# TC37XPD register map
Vendor: Infineon; Series: ATVMC; File version: 100
CPU: other r0p0, little endian, MPU, FPU, vendor SysTick, 4 interrupt priority bits
Registers are 32-bit, read-write, reset 0x0 unless marked. A register's access mark holds for its fields unless they carry their own. Offsets are from the block's base; [hi:lo] are bit positions; {n}, {i} and the like mark numbered series.

## ERAY0 (part 2 of 3) — ERAY
Base 0xF001C000
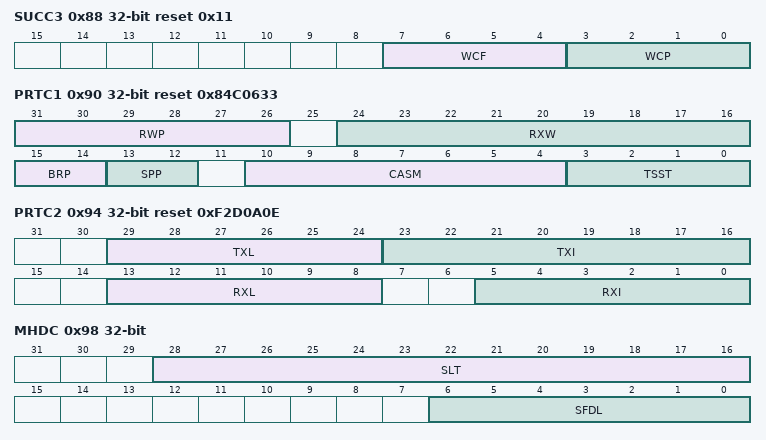
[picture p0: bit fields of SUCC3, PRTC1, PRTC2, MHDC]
0x88 SUCC3 reset 0x11 — SUC Configuration Register 3 resetvalue={Application Reset:0x11}
  [7:4] WCF — Maximum Without Clock Correction Fatal gMaxWithoutClockCorrecti on Fatal WCF. Defines the number of consecutive even odd cycle pairs with missing clock correction terms that will cause a transition from 8220 NORMAL ACTIVE 8221 or 8220 NORMAL PASSIVE 8221 to 8220 HALT 8221 state. Must be identical in all nodes of a cluster. Valid values are 1 to 15 1 H to F H cycle pairs.
  [3:0] WCP — Maximum Without Clock Correction Passive gMaxWithoutClockCorrectionPassive WCP. Defines the number of consecutive even odd cycle pairs with missing clock correction terms that will cause a transition from 8220 NORMAL ACTIVE 8221 to 8220 NORMAL PASSIVE 8221 state. Must be identical in all nodes of a cluster. Valid values are 1 to 15 1 H to F H cycle pairs.
0x8C NEMC — NEM Configuration Register resetvalue={Application Reset:0x0}
  [3:0] NML — Network Management Vector Length gNetworkManagementVectorLength NML. These bits configure the length of the NM Vector. The configured length must be identical in all nodes of a cluster. Valid values are 0 to 12 0 H to C H bytes.
0x90 PRTC1 reset 0x84C0633 — PRT Configuration Register 1 resetvalue={Application Reset:0x084C0633}
  [31:26] RWP — Repetitions of Tx Wakeup Pattern pWakeupPattern RWP. Configures the number of repetitions sequences of the Tx wakeup symbol. Valid values are 2 to 63 2 H to 3F H .
  [24:16] RXW — Wakeup Symbol Receive Window Length gdWakeupSymbolRxWindow RXW. Configures the number of Bit Times used by the node to test the duration of the received wakeup pattern. Must be identical in all nodes of a cluster. Valid values are 76 to 301 4C H to 12D H Bit Times.
  [15:14] BRP — Baud Rate Prescaler gdSampleClockPeriod pSamplePerMicrotick BRP. The baud rate prescaler configures the baud rate on the FlexRay 8482 bus. The baud rates listed below are valid with a sample clock f SCLK 80 160 MHz. One bit time always consists of 8 samples independent of the configured baud rate.
  [13:12] SPP — Strobe Point Position SPP. Defines the sample count value for strobing. The strobed bit value is set to the voted value when the sample count is incremented to the value configured by SPP. The current revision 2.1 of the FlexRay 8482 protocol requires that SPP 00 B . The alternate strobe point positions could be used to compensate for asymmetries in the physical layer.
  [10:4] CASM — Collision Avoidance Symbol Maximum gdCASRxLowMax CASM. Configures the upper limit of the acceptance window for a collision avoidance symbol CAS . Valid values are 67 to 99 43 H to 63 H . Most significant bit of CASM is hard wired to 1 and can not be modified.
  [3:0] TSST — Transmission Start Sequence Transmitter gdTSSTransmitter TSST. Configures the duration of the Transmission Start Sequence TSS in terms of Bit Times 1 bit time 160 4 160 Microticks 160 100ns at 10Mbps . Must be identical in all nodes of a cluster. Valid values are 3 to 15 3 H to F H Bit Times.
0x94 PRTC2 reset 0xF2D0A0E — PRT Configuration Register 2 resetvalue={Application Reset:0x0F2D0A0E}
  [29:24] TXL — Wakeup Symbol Transmit Low gdWakeupSymbolTxLow TXL. Configures the number of Bit Times used by the node to transmit the low phase of the wakeup symbol. Must be identical in all nodes of a cluster. Valid values are 15 to 60 F H to 3C H Bit Times.
  [23:16] TXI — Wakeup Symbol Transmit Idle gdWakeupSymbolTxIdle TXI. Configures the number of Bit Times used by the node to transmit the idle phase of the wakeup symbol. Must be identical in all nodes of a cluster. Valid values are 45 to 180 2D H to B4 H Bit Times.
  [13:8] RXL — Wakeup Symbol Receive Low gdWakeupSymbolRxLow RXL. Configures the number of Bit Times used by the node to test the duration of the low phase of the received wakeup symbol. Must be identical in all nodes of a cluster. Valid values are 10 to 55 A H to 37 H Bit Times.
  [5:0] RXI — Wakeup Symbol Receive Idle gdWakeupSymbolRxIdle RXI. Configures the number of Bit Times used by the node to test the duration of the idle phase of the received wakeup symbol. Must be identical in all nodes of a cluster. Valid values are 14 to 59 E H to 3B H Bit Times.
0x98 MHDC — MHD Configuration Register resetvalue={Application Reset:0x0}
  [28:16] SLT — Start of Latest Transmit pLatestTx SLT. Configures the maximum minislot value allowed before inhibiting Frame transmission in the dynamic segment of the cycle. There is no transmission dynamic segment if SLT is reset to zero. Valid values are 0 to 7981 0 to 1F2D H minislots.
  [6:0] SFDL — Static Frame Data Length gPayloadLengthStatic SFDL. Configures the cluster wide payload length for all Frames sent in the static segment in double byte. The payload length must be identical in all nodes of a cluster. Valid values are 0 to 127 0 to 7F H .
0xA0 GTUC01 reset 0x280 — GTU Configuration Register 1 resetvalue={Application Reset:0x280}
  [19:0] UT — Microtick per Cycle pMicroPerCycle UT. Configures the duration of the communication cycle in Microticks. Valid values are 640 to 640000 280 H to 9C400 H Microticks.
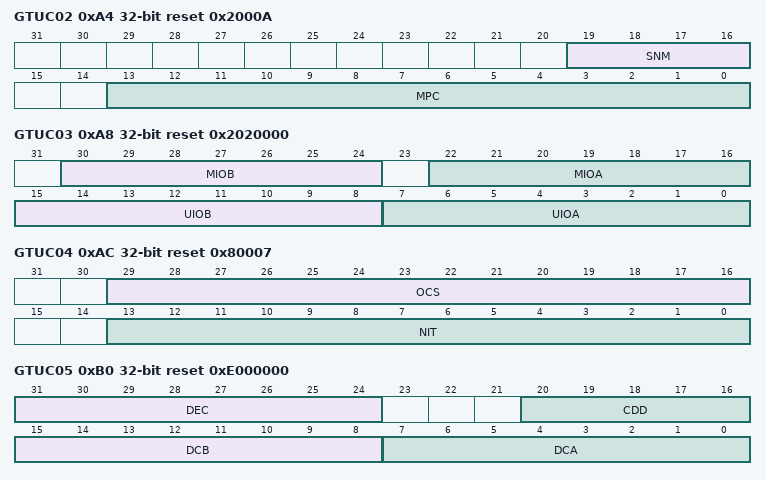
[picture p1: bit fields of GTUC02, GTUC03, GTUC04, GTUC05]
0xA4 GTUC02 reset 0x2000A — GTU Configuration Register 2 resetvalue={Application Reset:0x2000A}
  [19:16] SNM — Sync Node Max gSyncNodeMax SNM. Maximum number of Frames within a cluster with SYNC Frame indicator bit SYN set to 1. Must be identical in all nodes of a cluster. Valid values are 2 to 15 2 H to F H .
  [13:0] MPC — Macrotick Per Cycle gMacroPerCycle MPC. Configures the duration of one communication cycle in Macroticks. The cycle length must be identical in all nodes of a cluster. Valid values are 10 to 16000 A H to 3E80 H Macroticks.
0xA8 GTUC03 reset 0x2020000 — GTU Configuration Register 3 resetvalue={Application Reset:0x2020000}
  [30:24] MIOB — Macrotick Initial Offset Channel B gMacroInitialOffset B MIOB. Configures the number of Macroticks between the static slot boundary and the subsequent Macrotick boundary of the secondary time reference point based on the nominal Macrotick duration. Must be identical in all nodes of a cluster. Valid values are 2 to 72 2 H to 48 H Macroticks.
  [22:16] MIOA — Macrotick Initial Offset Channel A gMacroInitialOffset A MIOA. Configures the number of Macroticks between the static slot boundary and the subsequent Macrotick boundary of the secondary time reference point based on the nominal Macrotick duration. Must be identical in all nodes of a cluster. Valid values are 2 to 72 2 H to 48 H Macroticks.
  [15:8] UIOB — Microtick Initial Offset Channel B pMicroInitialOffset B UIOB. Configures the number of Microticks between the actual time reference point on channel B and the subsequent Macrotick boundary of the secondary time reference point. The parameter depends on pDelayCompensation B and therefore has to be set for each channel independently. Valid values are 0 to 240 0 H to F0 H Microticks.
  [7:0] UIOA — Microtick Initial Offset Channel A pMicroInitialOffset A UIOA. Configures the number of Microticks between the actual time reference point on channel A and the subsequent Macrotick boundary of the secondary time reference point. The parameter depends on pDelayCompensation A and therefore has to be set for each channel independently. Valid values are 0 to 240 0 H to F0 H Microticks.
0xAC GTUC04 reset 0x80007 — GTU Configuration Register 4 resetvalue={Application Reset:0x080007}
  [29:16] OCS — Offset Correction Start gOffsetCorrectionStart 1 OCS. Determines the start of the offset correction within the network idle time NIT phase calculated from start of cycle. Must be identical in all nodes of a cluster. For cluster consisting of E Ray implementations only it is sufficient to program OCS NIT 1. Valid values are 8 to 15998 8 H to 3E7E H Macroticks.
  [13:0] NIT — Network Idle Time Start gMacroPerCycle gdNIT 1 NIT. Configures the starting point of the Network Idle Time NIT at the end of the communication cycle expressed in terms of Macroticks from the beginning of the cycle. The start of network idle time NIT is recognized if Macrotick gMacroPerCycle gdNIT 1 and the increment pulse of Macrotick is set. Must be identical in all nodes of a cluster. Valid values are 7 to 15997 7 H to 3E7D H Macroticks.
0xB0 GTUC05 reset 0xE000000 — GTU Configuration Register 5 resetvalue={Application Reset:0x0E000000}
  [31:24] DEC — Decoding Correction pDecodingCorrection DEC. Configures the decoding correction value used to determine the primary time reference point. Valid values are 14 to 143 E H to 8F H Microticks.
  [20:16] CDD — Cluster Drift Damping pClusterDriftDamping CDD. Configures the cluster drift damping value used in clock synchronization to minimize accumulation of rounding errors. Valid values are 0 to 20 0 H to 14 H Microticks.
  [15:8] DCB — Delay Compensation Channel B pDelayCompensation B DCB. Used to compensate for reception delays on channel B. This covers assumed propagation delay up to cPropagationDelayMax for Microticks in the range of 0.0125 to 0.05 160 181 s. In practice the minimum of the propagation delays of all sync nodes should be applied. Valid values are 0 to 200 0 H to C8 H Microticks.
  [7:0] DCA — Delay Compensation Channel A pDelayCompensation A DCA. Used to compensate for reception delays on channel A. This covers assumed propagation delay up to cPropagationDelayMax for Microticks in the range of 0.0125 160 181 s to 0.05 160 181 s. In practice the minimum of the propagation delays of all sync nodes should be applied. Valid values are 0 to 200 0 H to C8 H Microticks.
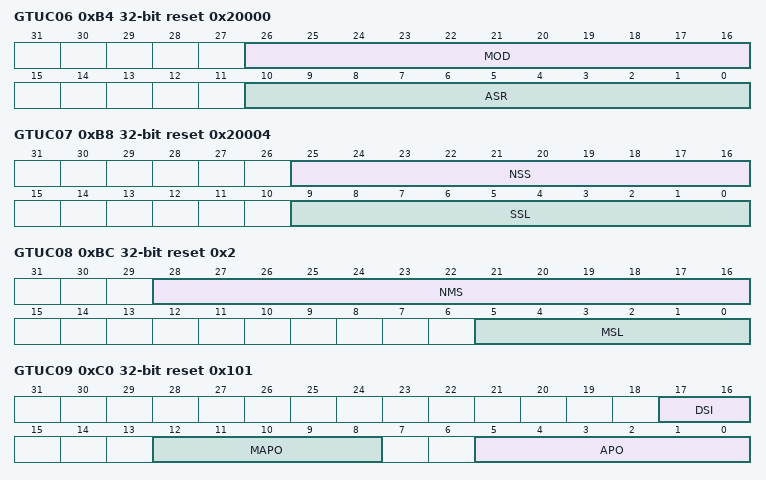
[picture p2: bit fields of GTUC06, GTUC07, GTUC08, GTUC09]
0xB4 GTUC06 reset 0x20000 — GTU Configuration Register 6 resetvalue={Application Reset:0x20000}
  [26:16] MOD — Maximum Oscillator Drift pdMaxDrift 1 MOD. Maximum drift offset between two nodes that operate with unsynchronized clocks over one communication cycle in Microticks. Valid values are 2 to 1923 2 H to 783 H Microticks.
  [10:0] ASR — Accepted Startup Range pdAcceptedStartupRange ASR. Number of Microticks constituting the expanded range of measured deviation for startup Frames during integration. Valid values are 0 to 1875 0 H to 753 H Microticks.
0xB8 GTUC07 reset 0x20004 — GTU Configuration Register 7 resetvalue={Application Reset:0x20004}
  [25:16] NSS — Number of Static Slots gNumberOfStaticSlots NSS. Configures the number of static slots in a cycle. At least 2 coldstart nodes must be configured to startup a FlexRay 8482 network. The number of static slots must be identical in all nodes of a cluster. Valid values are 2 to 1023 2 H to 3FF H .
  [9:0] SSL — Static Slot Length gdStaticSlot SSL. Configures the duration of a static slot in Macroticks. The static slot length must be identical in all nodes of a cluster. Valid values are 4 to 659 4 H to 293 H Macroticks.
0xBC GTUC08 reset 0x2 — GTU Configuration Register 8 resetvalue={Application Reset:0x2}
  [28:16] NMS — Number of Minislots gNumberOfMinislots NMS. Configures the number of minislots within the dynamic segment of a cycle. The number of minislots must be identical in all nodes of a cluster. Valid values are 0 to 7986 0 H to 1F32 H .
  [5:0] MSL — Minislot Length gdMinislot MSL. Configures the duration of a minislot in Macroticks. The minislot length must be identical in all nodes of a cluster. Valid values are 2 to 63 2 H to 3F H Macroticks.
0xC0 GTUC09 reset 0x101 — GTU Configuration Register 9 resetvalue={Application Reset:0x101}
  [17:16] DSI — Dynamic Slot Idle Phase gdDynamicSlotIdlePhase DSI. The duration of the dynamic slot idle phase has to be greater or equal than the idle detection time. Must be identical in all nodes of a cluster. Valid values are 0 to 2 Minislot.
  [12:8] MAPO — Minislot Action Point Offset gd Minislot Action Point Offset MAPO. Configures the action point offset in Macroticks within the minislots of the dynamic segment. Must be identical in all nodes of a cluster. Valid values are 1 to 31 1 H to 1F H Macroticks.
  [5:0] APO — Action Point Offset gdActionPointOffset APO. Configures the action point offset in Macroticks within static slots and symbol window. Must be identical in all nodes of a cluster. Valid values are 1 to 63 1 H to 3F H Macroticks.
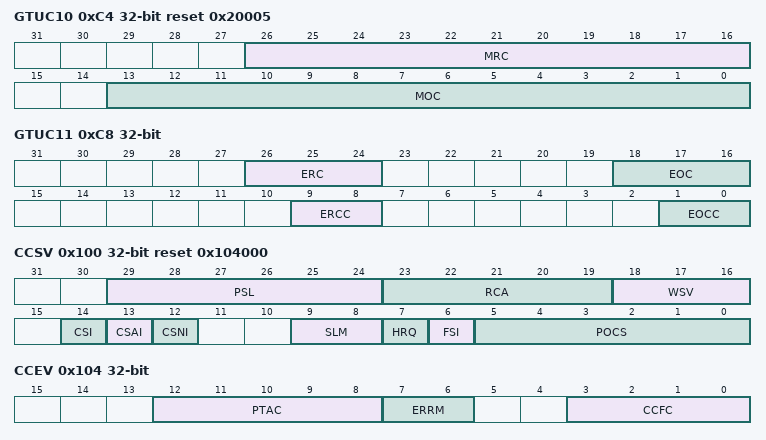
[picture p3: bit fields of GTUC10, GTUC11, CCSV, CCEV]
0xC4 GTUC10 reset 0x20005 — GTU Configuration Register 10 resetvalue={Application Reset:0x20005}
  [26:16] MRC — Maximum Rate Correction pRateCorrectionOut MRC. Holds the maximum permitted rate correction value to be applied by the internal clock synchronization algorithm. The communication controller checks only the internal rate correction value against the maximum rate correction value absolute value . Valid values are 2 to 1923 2 H to 783 H Microticks.
  [13:0] MOC — Maximum Offset Correction pOffsetCorrectionOut MOC. Holds the maximum permitted offset correction value to be applied by the internal clock synchronization algorithm absolute value . The Communication Controller checks only the internal offset correction value against the maximum offset correction value. Valid values are 5 to 15266 5 H to 3BA2 H Microticks.
0xC8 GTUC11 — GTU Configuration Register 11 resetvalue={Application Reset:0x0}
  [26:24] ERC — External Rate Correction pExternRateCorrection ERC. Holds the external rate correction value in Microticks to be applied by the internal clock synchronization algorithm. The value is subtracted added from to the calculated rate correction value. The value is applied during network idle time NIT . Can be modified in 8220 DEFAULT CONFIG 8221 or 8220 CONFIG 8221 state only. Valid values are 0 to 7 Microticks.
  [18:16] EOC — External Offset Correction pExternOffsetCorrection EOC. Holds the external clock offset correction value in Microticks to be applied by the internal synchronization algorithm. The value is subtracted added from to the calculated offset correction value. The value is applied during network idle time NIT . May be modified in 8220 DEFAULT CONFIG 8221 or 8220 CONFIG 8221 state only. Valid values are 0 to 7 Microticks.
  [9:8] ERCC — External Rate Correction Control pExternRateControl ERCC. By writing to ERCC the external rate correction is enabled as specified below. Should be modified only outside network idle time NIT .
  [1:0] EOCC — External Offset Correction Control pExternOffsetControl EOCC. By writing to EOCC the external offset correction is enabled as specified below. Should be modified only outside network idle time NIT .
0x100 CCSV ro reset 0x104000 — Communication Controller Status Vector resetvalue={Application Reset:0x104000}
  [29:24] PSL — POC Status Log PSL. Status of CCSV.POCS immediately before entering 8220 HALT 8221 state. Set when entering 8220 HALT 8221 state. Set to 8220 HALT 8221 when FREEZE command is applied during 8220 HALT 8221 state. Reset to 000000 B when leaving 8220 HALT 8221 state.
  [23:19] RCA — Remaining Coldstart Attempts vRemainingColdstartAttempts RCA. Indicates the number of remaining coldstart attempts. The RUN command resets this counter to the maximum number of coldstart attempts as configured by SUCC1.CSA.
  [18:16] WSV — Wakeup Status vPOC WakeupStatus WSV. Indicates the status of the current wakeup attempt. Reset by CHI command 8220 RESET STATUS INDICATORS 8221 or by transition from 8220 HALT 8221 to 8220 DEFAULT CONFIG 8221 state.
  [14] CSI — Cold Start Inhibit vColdStartInhibit CSI. Indicates that the node is disabled from cold starting. The flag is set whenever the POC enters 8220 READY 8221 state due to CHI command 8220 READY 8221 . The flag has to be reset under control of the Host by CHI command 8220 ALLOW COLDSTART 8221 SUCC1.CMD 160 160 1001 B .
  [13] CSAI — Coldstart Abort Indicator CSAI. Coldstart aborted. Reset by CHI command 8220 RESET STATUS INDICATORS 8221 or by transition from 8220 HALT 8221 to 8220 DEFAULT CONFIG 8221 state or from 8220 READY 8221 to 8220 STARTUP 8221 state.
  [12] CSNI — Coldstart Noise Indicator vPOC ColdstartNoise CSNI. Indicates that the cold start procedure occurred under noisy conditions. Reset by CHI command 8220 RESET STATUS INDICATORS 8221 or by transition from 8220 HALT 8221 to 8220 DEFAULT CONFIG 8221 state or from 8220 READY 8221 to 8220 STARTUP 8221 state.
  [9:8] SLM — Slot Mode vPOC SlotMode SLM. Indicates the actual slot mode of the POC in states READY WAKEUP STARTUP NORMAL ACTIVE and NORMAL PASSIVE. Default is 8220 SINGLE 8221 . Changes to 8220 ALL 8221 depending on configuration bit SUCC1.TSM. In 8220 NORMAL ACTIVE 8221 or 8220 NORMAL PASSIVE 8221 state the CHI command 8220 ALL SLOTS 8221 will change the slot mode from 8220 SINGLE 8221 over 8220 ALL PENDING 8221 to 8220 ALL 8221 . Set to SINGLE in all other states.
  [7] HRQ — Halt Request vPOC CHIHaltRequest HRQ. Indicates that a request from the Host has been received to halt the POC at the end of the communication cycle. Reset by transition from 8220 HALT 8221 to 8220 DEFAULT CONFIG 8221 state or when entering 8220 READY 8221 state.
  [6] FSI — Freeze Status Indicator vPOC Freeze FSI. Indicates that the POC has entered the 8220 HALT 8221 state due to CHI command 8220 FREEZE 8221 or due to an error condition requiring an immediate POC halt. Reset by transition from 8220 HALT 8221 to 8220 DEFAULT CONFIG 8221 state.
  [5:0] POCS — Protocol Operation Control Status POCS. 00 H ... 05 H 0F H Indicates the actual state of operation of the Communication Controller Protocol Operation Control 06 H 160 8230 160 14 H are reserved. 10 H ... 13 H Indicates the actual state of operation of the POC in the wakeup path 14 H 160 8230 160 1F H are reserved. 20 H ... 2B H Indicates the actual state of operation of the POC in the startup path 2C H 160 8230 160 3F H are reserved.
0x104 CCEV ro — Communication Controller Error Vector resetvalue={Application Reset:0x0}
  [12:8] PTAC — Passive to Active Count vAllowPassiveToActive PTAC. Indicates the number of consecutive even odd cycle pairs that have passed with valid rate and offset correction terms while the node is waiting to transit from NORMAL PASSIVE state to NORMAL ACTIVE state. The transition takes place when PTAC equals SUCC1.PTA 1.
  [7:6] ERRM — Error Mode vPOC ErrorMode ERRM. Indicates the actual error mode of the POC.
  [3:0] CCFC — Clock Correction Failed Counter vClockCorrectionFailed CCFC. The Clock Correction Failed Counter is incremented by one at the end of any odd communication cycle where either the missing offset correction error or missing rate correction error are active. The Clock Correction Failed Counter is reset to 0 at the end of an odd communication cycle if neither the offset correction failed nor the rate correction failed errors are active. The Clock Correction Failed Counter stops at 15.
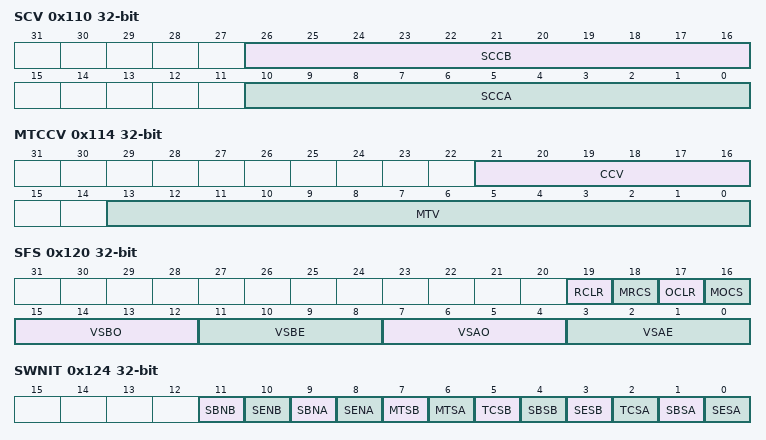
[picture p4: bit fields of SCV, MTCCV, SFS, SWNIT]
0x110 SCV ro — Slot Counter Value resetvalue={Application Reset:0x0}
  [26:16] SCCB — Slot Counter Channel B vSlotCounter B SCCB. Current slot counter value on channel B. The value is incremented by the Communication Controller and reset at the start of a communication cycle. Valid values are 0 to 2047 0 H to 7FF H .
  [10:0] SCCA — Slot Counter Channel A vSlotCounter A SCCA. Current slot counter value on channel A. The value is incremented by the Communication Controller and reset at the start of a communication cycle. Valid values are 0 to 2047 0 H to 7FF H .
0x114 MTCCV ro — Macrotick and Cycle Counter Value resetvalue={Application Reset:0x0}
  [21:16] CCV — Cycle Counter Value vCycleCounter CCV. Current cycle counter value. The value is incremented by the Communication Controller at the start of a communication cycle. Valid values are 0 to 63 0 H to 3F H .
  [13:0] MTV — Macrotick Value vMacrotick MTV. Current Macrotick value. The value is incremented by the Communication Controller and reset at the start of a communication cycle. Valid values are 0 to 16000 0 H to 3E80 H .
0x118 RCV ro — Rate Correction Value resetvalue={Application Reset:0x0}
  [11:0] RCV — Rate Correction Value vRateCorrection RCV. Rate correction value two s complement . Calculated internal rate correction value before limitation. If the RCV value exceeds the limits defined by GTUC10.MRC flag SFS.RCLR is set to 1.
0x11C OCV ro — Offset Correction Value resetvalue={Application Reset:0x0}
  [18:0] OCV — Offset Correction Value vOffsetCorrection OCV. Offset correction value two s complement . Calculated internal offset correction value before limitation. If the OCV value exceeds the limits defined by GTUC10.MOC flag SFS.OCLR is set to 1.
0x120 SFS ro — SYNC Frame Status resetvalue={Application Reset:0x0}
  [19] RCLR — Rate Correction Limit Reached RCLR. The Rate Correction Limit Reached flag signals to the Host that the rate correction value has exceeded its limit.as defined by GTUC10.MRC. The flag is updated by the Communication Controller at start of offset correction phase.
  [18] MRCS — Missing Rate Correction Signal MRCS. The Missing Rate Correction Flag signals to the Host that no rate correction calculation can be performed because no pairs of even odd SYNC Frames were received. The flag is updated by the Communication Controller at start of offset correction phase.
  [17] OCLR — Offset Correction Limit Reached OCLR. The Offset Correction Limit Reached flag signals to the Host that the offset correction value has exceeded its limit as defined by GTUC10.MOC. The flag is updated by the Communication Controller at start of offset correction phase.
  [16] MOCS — Missing Offset Correction Signal MOCS. The Missing Offset Correction flag signals to the Host that no offset correction calculation can be performed because no SYNC Frames were received. The flag is updated by the Communication Controller at start of offset correction phase.
  [15:12] VSBO — Valid SYNC Frames Channel B odd communication cycle VSBO. Holds the number of valid SYNC Frames received on channel B in the odd communication cycle. If transmission of SYNC Frames is enabled by SUCC1.TXSY the value is incremented by one. The value is updated during the network idle time NIT of each odd communication cycle. This bit field is only valid if the channel B is assigned to the Communication Controller by SUCC1.CCHB.
  [11:8] VSBE — Valid SYNC Frames Channel B even communication cycle VSBE. Holds the number of valid SYNC Frames received on channel B in the even communication cycle. If transmission of SYNC Frames is enabled by SUCC1.TXSY the value is incremented by one. The value is updated during the network idle time NIT of each even communication cycle. This bit field is only valid if the channel B is assigned to the Communication Controller by SUCC1.CCHB.
  [7:4] VSAO — Valid SYNC Frames Channel A odd communication cycle VSAO. Holds the number of valid SYNC Frames received on channel A in the odd communication cycle. If transmission of SYNC Frames is enabled by SUCC1.TXSY the value is incremented by one. The value is updated during the network idle time NIT of each odd communication cycle. This bit field is only valid if the channel A is assigned to the Communication Controller by SUCC1.CCHA.
  [3:0] VSAE — Valid SYNC Frames Channel A even communication cycle VSAE. Holds the number of valid SYNC Frames received on channel A in the even communication cycle. If transmission of SYNC Frames is enabled by SUCC1.TXSY the value is incremented by one. The value is updated during the network idle time NIT of each even communication cycle. This bit field is only valid if the channel A is assigned to the Communication Controller by SUCC1.CCHA.
0x124 SWNIT ro — Symbol Window and Network Idle Time Status resetvalue={Application Reset:0x0}
  [11] SBNB — Slot Boundary Violation during network idle time NIT Channel B vSS BViolationB SBNB. Updated by the Communication Controller channel B at the end of the NIT.
  [10] SENB — Syntax Error during network idle time NIT Channel B vSS SyntaxErrorB SENB. Updated by the Communication Controller channel B at the end of the NIT.
  [9] SBNA — Slot Boundary Violation during network idle time NIT Channel A vSS BViolationA SBNA. Updated by the Communication Controller channel A at the end of the NIT.
  [8] SENA — Syntax Error during network idle time NIT Channel A vSS SyntaxErrorA SENA. Updated by the Communication Controller channel A at the end of the NIT.
  [7] MTSB — MTS Received on Channel B vSS ValidMTSB MTSB. Media Access Test symbol received on channel B during the proceeding symbol window. Updated by the Communication Controller for each channel at the end of the symbol window. When this bit is set to 1 also interrupt flag SIR.MTSB is set to 1.
  [6] MTSA — MTS Received on Channel A vSS ValidMTSA MTSA. Media Access Test symbol received on channel A during the proceeding symbol window. Updated by the Communication Controller for each channel at the end of the symbol window. When this bit is set to 1 also interrupt flag SIR.MTSA is set to 1.
  [5] TCSB — Transmission Conflict in Symbol Window Channel B vSS TxConflictB TCSB
  [4] SBSB — Slot Boundary Violation in Symbol Window Channel B vSS BViolationB SBSB
  [3] SESB — Syntax Error in Symbol Window Channel B vSS SyntaxErrorB SESB
  [2] TCSA — Transmission Conflict in Symbol Window Channel A vSS TxConflictA TCSA
  [1] SBSA — Slot Boundary Violation in Symbol Window Channel A vSS BViolationA SBSA
  [0] SESA — Syntax Error in Symbol Window Channel A vSS SyntaxErrorA SESA
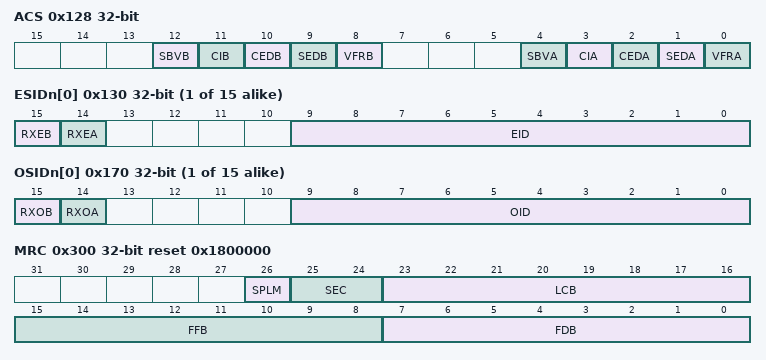
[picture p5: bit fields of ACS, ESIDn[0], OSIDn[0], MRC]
0x128 ACS — Aggregated Channel Status resetvalue={Application Reset:0x0}
  [12] SBVB — Slot Boundary Violation on Channel B vSS BViolationB SBVB. One or more slot boundary violations were observed on channel B at any time during the observation period static or dynamic slots symbol window and network idle time NIT .
  [11] CIB — Communication Indicator Channel B CIB. One or more valid Frames were received on channel B in slots that also contained any additional communication during the observation period i.e. one or more slots received a valid Frame AND had any combination of either syntax error OR content error OR slot boundary violation.
  [10] CEDB — Content Error Detected on Channel B vSS ContentErrorB CEDB. One or more Frames with a content error were received on channel B in any static or dynamic slot during the observation period.
  [9] SEDB — Syntax Error Detected on Channel B vSS SyntaxErrorB SEDB. One or more syntax errors in static or dynamic slots symbol window and network idle time NIT were observed on channel B.
  [8] VFRB — Valid Frame Received on Channel B vSS ValidFrameB VFRB. One or more valid Frames were received on channel B in any static or dynamic slot during the observation period.
  [4] SBVA — Slot Boundary Violation on Channel A vSS BViolationA SBVA. One or more slot boundary violations were observed on channel A at any time during the observation period static or dynamic slots symbol window and network idle time NIT .
  [3] CIA — Communication Indicator Channel A CIA. One or more valid Frames were received on channel A in slots that also contained any additional communication during the observation period i.e. one or more slots received a valid Frame AND had any combination of either syntax error OR content error OR slot boundary violation.
  [2] CEDA — Content Error Detected on Channel A vSS ContentErrorA CEDA. One or more Frames with a content error were received on channel A in any static or dynamic slot during the observation period.
  [1] SEDA — Syntax Error Detected on Channel A vSS SyntaxErrorA SEDA. One or more syntax errors in static or dynamic slots symbol window and network idle time NIT were observed on channel A.
  [0] VFRA — Valid Frame Received on Channel A vSS ValidFrameA VFRA. One or more valid Frames were received on channel A in any static or dynamic slot during the observation period.
{0x130+4i} ESIDn[{i}] (i=0..14) ro — Even Sync ID Symbol Window 01 resetvalue={Application Reset:0x0}
  [15] RXEB — Received Configured Even Sync ID on Channel B RXEB. Signals that a SYNC Frame corresponding to the stored even sync ID was received on channel B or that the node is configured to be a sync node with key slot EID ESID1 only .
  [14] RXEA — Received Configured Even Sync ID on Channel A RXEA. Signals that a SYNC Frame corresponding to the stored even sync ID was received on channel A or that the node is configured to be a sync node with key slot EID ESID1 only .
  [9:0] EID — Even Sync ID vsSyncIDListA B even EID. SYNC Frame ID even communication cycle.
{0x170+4i} OSIDn[{i}] (i=0..14) ro — Odd Sync ID Symbol Window 01 resetvalue={Application Reset:0x0}
  [15] RXOB — Received Odd Sync ID on Channel B RXOB. Signals that a SYNC Frame corresponding to the stored odd sync ID was received on channel B or that the node is configured to be a sync node with key slot OID OSID1 only
  [14] RXOA — Received Odd Sync ID on Channel A RXOA. Signals that a SYNC Frame corresponding to the stored odd sync ID was received on channel A or that the node is configured to be a sync node with key slot OID OSID1 only .
  [9:0] OID — Odd Sync ID vsSyncIDListA B odd OID. SYNC Frame ID even communication cycle.
{0x1B0+4i} NMVx[{i}] (i=0..2) ro — Network Management Vector 1 resetvalue={Application Reset:0x0}
  [31:0] NM — Network Management Vector NM
0x300 MRC reset 0x1800000 — Message RAM Configuration resetvalue={Application Reset:0x1800000}
  [26] SPLM — SYNC Frame Payload Multiplex SPLM. This bit is only evaluated if the node is configured as sync node SUCC1.TXSY 1 or for single slot mode operation SUCC1.TSM 1 . When this bit is set to 1 Message Buffers 0 and 1 are dedicated for SYNC Frame transmission with different payload data on channel A and B. When this bit is reset to 0 SYNC Frames are transmitted from Message Buffer 0 with the same payload data on both channels. Note that the channel filter configuration for Message Buffer 0 resp. Message Buffer 1 has to be chosen accordingly.
  [25:24] SEC — Secure Buffers SEC. Not evaluated when the Communication Controller is in 8220 DEFAULT CONFIG 8221 or 8220 CONFIG 8221 state. For temporary unlocking see 8220 Host Handling of Errors 8221 . In nodes configured for SYNC Frame transmission or for single slot mode operation Message Buffer 0 and if SPLM 1 also Message Buffer 1 Reconfiguration of all Message Buffers is always locked
  [23:16] LCB — Last Configured Buffer LCB. May be only modified in DEFAULT CONFIG or CONFIG state.
  [15:8] FFB — First Buffer of FIFO FFB. May be modified in DEFAULT CONFIG or CONFIG state only.
  [7:0] FDB — First Dynamic Buffer FDB. May be modified in DEFAULT CONFIG or CONFIG state only.
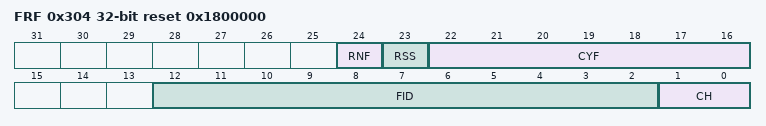
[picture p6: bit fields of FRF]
0x304 FRF reset 0x1800000 — FIFO Rejection Filter resetvalue={Application Reset:0x1800000}
  [24] RNF — Reject NULL Frames RNF. If this bit is set received NULL Frames are not stored in the FIFO. May be modified in DEFAULT CONFIG or CONFIG state only.
  [23] RSS — Reject in Static Segment RSS. If this bit is set the FIFO is used only be used in dynamic segment. May be modified in DEFAULT CONFIG or CONFIG state only.
  [22:16] CYF — Cycle Counter Filter CYF. The 7 bit cycle counter filter determines the cycle set to which Frame ID and channel rejection filter are applied. In cycles not belonging to the cycle set specified by CYF all Frames are rejected. For details about the configuration of the cycle counter filter see 8220 Cycle Counter Filtering 8221 . May be modified in 8220 DEFAULT CONFIG 8221 or 8220 CONFIG 8221 state only.
  [12:2] FID — Frame ID Filter FID. Determines the Frame ID to be rejected by the FIFO. With the additional configuration of register FRFM the corresponding Frame ID filter bits are ignored which results in further rejected Frame IDs. When FRFM.MFID is zero a Frame ID filter value of zero means that no Frame ID is rejected.
  [1:0] CH — Channel Filter CH. May be modified in DEFAULT CONFIG or CONFIG state only.
0x308 FRFM — FIFO Rejection Filter Mask resetvalue={Application Reset:0x0}
  [12:2] MFID — Mask Frame ID Filter MFID. May be modified in 8220 DEFAULT CONFIG 8221 or 8220 CONFIG 8221 state only. When 0 written in a bit position the corresponding Frame ID filter bit is used for rejection filtering. When 1 written in a bit position the corresponding Frame ID filter bit is ignored. Valid values are from 0x000 0x3FF.
0x30C FCL reset 0x80 — FIFO Critical Level resetvalue={Application Reset:0x080}
  [7:0] CL — Critical Level CL. When the receive FIFO fill level FSR.RFFL is equal or greater than the critical level configured by CL the receive FIFO critical level flag FSR.RFCL is set. If CL is programmed to values gt 128 bit FSR.RFCL is never set. When FSR.RFCL changes from 0 to 1 bit SIR.RFCL is set to 1 and if enabled a service request is generated.
